# ESP32-C5 register map
Vendor: ESPRESSIF SYSTEMS (SHANGHAI) CO., LTD.; Series: ESP32 C-Series; File version: 1
CPU: RV32IMAC r0p0, little endian, no MPU, no FPU, 0 interrupt priority bits
Address unit: 32 bits
Registers are 32-bit, read-write, reset 0x0 unless marked. A register's access mark holds for its fields unless they carry their own. Offsets are from the block's base; [hi:lo] are bit positions; {n}, {i} and the like mark numbered series.

## GPIO_EXT — GPIO_EXT Peripheral
Base 0x60091E00
0x00 CLOCK_GATE — Clock Gating Configure Register
  [0] CLK_EN — Clock enable bit of configuration registers for sigma delta modulation.
0x04 SIGMADELTA_MISC — MISC Register
  [0] SIGMADELTA_CLK_EN — Configures whether or not to enable the clock for sigma delta modulation.\\ 0: Not enable\\ 1: Enable\\%\label{fielddesc:GPIOSDSPISWAP}- [GPIOSD_SPI_SWAP] Reserved.
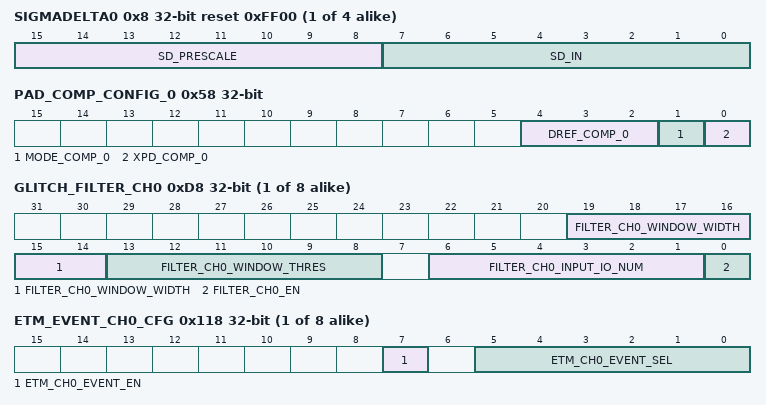
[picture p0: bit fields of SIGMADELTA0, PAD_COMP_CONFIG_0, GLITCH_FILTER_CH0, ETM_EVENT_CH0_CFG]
{0x8+4i} SIGMADELTA{i} (i=0..3) reset 0xFF00 — Duty cycle configuration register for SDM channel {i}
  [15:8] SD_PRESCALE — Configures the divider value to divide IO MUX operating clock. \\
  [7:0] SD_IN — Configures the duty cycle of sigma delta modulation output. \\
0x58 PAD_COMP_CONFIG_0 — Configuration register for zero-crossing detection
  [4:2] DREF_COMP_0 — Configures the internal reference voltage for analog PAD voltage coparator. \\ 0: Internal reference voltage is 0 * VDDPST1\\ 1: Internal reference voltage is 0.1 * VDDPST1\\ …...\\ 6: Internal reference voltage is 0.6 * VDDPST1\\ 7: Internal reference voltage is 0.7 * VDDPST1\\
  [1] MODE_COMP_0 — Configures the reference voltage for analog PAD voltage comparater.. \\ 0: Reference voltage is the internal reference voltage, meanwhile GPIO8 PAD can be used as a regular GPIO\\ 1: Reference voltage is the voltage on the GPIO8 PAD\\
  [0] XPD_COMP_0 — Configures whether to enable the function of analog PAD voltage comparator.\\ 0: Disable\\ 1: Enable\\
0x5C PAD_COMP_FILTER_0 — Configuration register for interrupt source mask period of zero-crossing detection
  [31:0] ZERO_DET_FILTER_CNT_0 — Configures the period of masking new interrupt source foe analog PAD voltage comparator.\\ Measurement unit: IO MUX operating clock cycle\\
{0xD8+4i} GLITCH_FILTER_CH{i} (i=0..7) — Glitch Filter Configure Register of Channel{i}
  [19:14] FILTER_CH0_WINDOW_WIDTH — Configures the window width for Glitch Filter. The effective value of window width is 0 ~ 63. \\ Measurement unit: IO MUX operating clock cycle\\
  [13:8] FILTER_CH0_WINDOW_THRES — Configures the window threshold for Glitch Filter. The window threshold should be less than or equal to GPIOSD_FILTER_CH%s_WINDOW_WIDTH.\\ %see DOC-4768\\ Measurement unit: IO MUX operating clock cycle\\
  [6:1] FILTER_CH0_INPUT_IO_NUM — Configures to select the input GPIO for Glitch Filter. \\ 0: Select GPIO0\\ 1: Select GPIO1\\ ......\\ 27: Select GPIO27\\ 28: Select GPIO28\\ 29 ~ 63: Reserved\\
  [0] FILTER_CH0_EN — Configures whether or not to enable channel %s of Glitch Filter.\\ 0: Not enable\\ 1: Enable\\
{0x118+4i} ETM_EVENT_CH{i}_CFG (i=0..7) — Etm Config register of Channel{i}
  [7] ETM_CH0_EVENT_EN — Configures whether or not to enable ETM event send.\\ 0: Not enable\\ 1: Enable\\
  [5:0] ETM_CH0_EVENT_SEL — Configures to select GPIO for ETM event channel.\\ 0: Select GPIO0\\ 1: Select GPIO1\\ ......\\ 27: Select GPIO27\\ 28: Select GPIO28\\ 29 ~ 63: Reserved\\
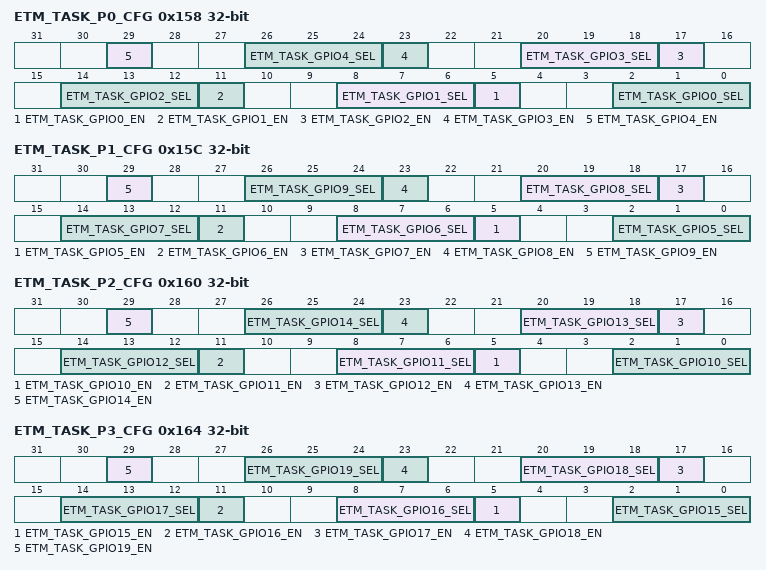
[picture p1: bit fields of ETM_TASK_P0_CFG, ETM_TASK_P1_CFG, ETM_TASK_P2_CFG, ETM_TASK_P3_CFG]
0x158 ETM_TASK_P0_CFG — GPIO selection register 0 for ETM
  [6n+5] ETM_TASK_GPIO{n}_EN (n=0..4) — Configures whether or not to enable GPIO{6n+5} to response ETM task.\\ 0: Not enable\\ 1: Enable\\
  [26:24] ETM_TASK_GPIO4_SEL — Configures to select an ETM task channel for GPIO24.\\ 0: Select channel 0\\ 1: Select channel 1\\ ......\\ 7: Select channel 7\\%\label{fielddesc:GPIOSDETMTASKGPIO1EN}- [GPIOSD_ETM_TASK_GPIO1_EN] Enable bit of GPIO response etm task. %\label{fielddesc:GPIOSDETMTASKGPIO1SEL}- [GPIOSD_ETM_TASK_GPIO1_SEL] GPIO choose a etm task channel. %\label{fielddesc:GPIOSDETMTASKGPIO2EN}- [GPIOSD_ETM_TASK_GPIO2_EN] Enable bit of GPIO response etm task. %\label{fielddesc:GPIOSDETMTASKGPIO2SEL}- [GPIOSD_ETM_TASK_GPIO2_SEL] GPIO choose a etm task channel. %\label{fielddesc:GPIOSDETMTASKGPIO3EN}\item [GPIOSD_ETM_TASK_GPIO3_EN] Enable bit of GPIO response etm task. %\label{fielddesc:GPIOSDETMTASKGPIO3SEL}\item [GPIOSD_ETM_TASK_GPIO3_SEL] GPIO choose a etm task channel.
  [20:18] ETM_TASK_GPIO3_SEL — Configures to select an ETM task channel for GPIO18.\\ 0: Select channel 0\\ 1: Select channel 1\\ ......\\ 7: Select channel 7\\%\label{fielddesc:GPIOSDETMTASKGPIO1EN}- [GPIOSD_ETM_TASK_GPIO1_EN] Enable bit of GPIO response etm task. %\label{fielddesc:GPIOSDETMTASKGPIO1SEL}- [GPIOSD_ETM_TASK_GPIO1_SEL] GPIO choose a etm task channel. %\label{fielddesc:GPIOSDETMTASKGPIO2EN}- [GPIOSD_ETM_TASK_GPIO2_EN] Enable bit of GPIO response etm task. %\label{fielddesc:GPIOSDETMTASKGPIO2SEL}- [GPIOSD_ETM_TASK_GPIO2_SEL] GPIO choose a etm task channel. %\label{fielddesc:GPIOSDETMTASKGPIO3EN}\item [GPIOSD_ETM_TASK_GPIO3_EN] Enable bit of GPIO response etm task. %\label{fielddesc:GPIOSDETMTASKGPIO3SEL}\item [GPIOSD_ETM_TASK_GPIO3_SEL] GPIO choose a etm task channel.
  [14:12] ETM_TASK_GPIO2_SEL — Configures to select an ETM task channel for GPIO12.\\ 0: Select channel 0\\ 1: Select channel 1\\ ......\\ 7: Select channel 7\\%\label{fielddesc:GPIOSDETMTASKGPIO1EN}- [GPIOSD_ETM_TASK_GPIO1_EN] Enable bit of GPIO response etm task. %\label{fielddesc:GPIOSDETMTASKGPIO1SEL}- [GPIOSD_ETM_TASK_GPIO1_SEL] GPIO choose a etm task channel. %\label{fielddesc:GPIOSDETMTASKGPIO2EN}- [GPIOSD_ETM_TASK_GPIO2_EN] Enable bit of GPIO response etm task. %\label{fielddesc:GPIOSDETMTASKGPIO2SEL}- [GPIOSD_ETM_TASK_GPIO2_SEL] GPIO choose a etm task channel. %\label{fielddesc:GPIOSDETMTASKGPIO3EN}\item [GPIOSD_ETM_TASK_GPIO3_EN] Enable bit of GPIO response etm task. %\label{fielddesc:GPIOSDETMTASKGPIO3SEL}\item [GPIOSD_ETM_TASK_GPIO3_SEL] GPIO choose a etm task channel.
  [8:6] ETM_TASK_GPIO1_SEL — Configures to select an ETM task channel for GPIO6.\\ 0: Select channel 0\\ 1: Select channel 1\\ ......\\ 7: Select channel 7\\%\label{fielddesc:GPIOSDETMTASKGPIO1EN}- [GPIOSD_ETM_TASK_GPIO1_EN] Enable bit of GPIO response etm task. %\label{fielddesc:GPIOSDETMTASKGPIO1SEL}- [GPIOSD_ETM_TASK_GPIO1_SEL] GPIO choose a etm task channel. %\label{fielddesc:GPIOSDETMTASKGPIO2EN}- [GPIOSD_ETM_TASK_GPIO2_EN] Enable bit of GPIO response etm task. %\label{fielddesc:GPIOSDETMTASKGPIO2SEL}- [GPIOSD_ETM_TASK_GPIO2_SEL] GPIO choose a etm task channel. %\label{fielddesc:GPIOSDETMTASKGPIO3EN}\item [GPIOSD_ETM_TASK_GPIO3_EN] Enable bit of GPIO response etm task. %\label{fielddesc:GPIOSDETMTASKGPIO3SEL}\item [GPIOSD_ETM_TASK_GPIO3_SEL] GPIO choose a etm task channel.
  [2:0] ETM_TASK_GPIO0_SEL — Configures to select an ETM task channel for GPIO0.\\ 0: Select channel 0\\ 1: Select channel 1\\ ......\\ 7: Select channel 7\\%\label{fielddesc:GPIOSDETMTASKGPIO1EN}- [GPIOSD_ETM_TASK_GPIO1_EN] Enable bit of GPIO response etm task. %\label{fielddesc:GPIOSDETMTASKGPIO1SEL}- [GPIOSD_ETM_TASK_GPIO1_SEL] GPIO choose a etm task channel. %\label{fielddesc:GPIOSDETMTASKGPIO2EN}- [GPIOSD_ETM_TASK_GPIO2_EN] Enable bit of GPIO response etm task. %\label{fielddesc:GPIOSDETMTASKGPIO2SEL}- [GPIOSD_ETM_TASK_GPIO2_SEL] GPIO choose a etm task channel. %\label{fielddesc:GPIOSDETMTASKGPIO3EN}\item [GPIOSD_ETM_TASK_GPIO3_EN] Enable bit of GPIO response etm task. %\label{fielddesc:GPIOSDETMTASKGPIO3SEL}\item [GPIOSD_ETM_TASK_GPIO3_SEL] GPIO choose a etm task channel.
0x15C ETM_TASK_P1_CFG — GPIO selection register 1 for ETM
  [6n-25] ETM_TASK_GPIO{n}_EN (n=5..9) — Configures whether or not to enable GPIO{6n-25} to response ETM task.\\ 0: Not enable\\ 1: Enable\\
  [26:24] ETM_TASK_GPIO9_SEL — Configures to select an ETM task channel for GPIO24.\\ 0: Select channel 0\\ 1: Select channel 1\\ ......\\ 7: Select channel 7\\%\label{fielddesc:GPIOSDETMTASKGPIO1EN}- [GPIOSD_ETM_TASK_GPIO1_EN] Enable bit of GPIO response etm task. %\label{fielddesc:GPIOSDETMTASKGPIO1SEL}- [GPIOSD_ETM_TASK_GPIO1_SEL] GPIO choose a etm task channel. %\label{fielddesc:GPIOSDETMTASKGPIO2EN}- [GPIOSD_ETM_TASK_GPIO2_EN] Enable bit of GPIO response etm task. %\label{fielddesc:GPIOSDETMTASKGPIO2SEL}- [GPIOSD_ETM_TASK_GPIO2_SEL] GPIO choose a etm task channel. %\label{fielddesc:GPIOSDETMTASKGPIO3EN}\item [GPIOSD_ETM_TASK_GPIO3_EN] Enable bit of GPIO response etm task. %\label{fielddesc:GPIOSDETMTASKGPIO3SEL}\item [GPIOSD_ETM_TASK_GPIO3_SEL] GPIO choose a etm task channel.
  [20:18] ETM_TASK_GPIO8_SEL — Configures to select an ETM task channel for GPIO18.\\ 0: Select channel 0\\ 1: Select channel 1\\ ......\\ 7: Select channel 7\\%\label{fielddesc:GPIOSDETMTASKGPIO1EN}- [GPIOSD_ETM_TASK_GPIO1_EN] Enable bit of GPIO response etm task. %\label{fielddesc:GPIOSDETMTASKGPIO1SEL}- [GPIOSD_ETM_TASK_GPIO1_SEL] GPIO choose a etm task channel. %\label{fielddesc:GPIOSDETMTASKGPIO2EN}- [GPIOSD_ETM_TASK_GPIO2_EN] Enable bit of GPIO response etm task. %\label{fielddesc:GPIOSDETMTASKGPIO2SEL}- [GPIOSD_ETM_TASK_GPIO2_SEL] GPIO choose a etm task channel. %\label{fielddesc:GPIOSDETMTASKGPIO3EN}\item [GPIOSD_ETM_TASK_GPIO3_EN] Enable bit of GPIO response etm task. %\label{fielddesc:GPIOSDETMTASKGPIO3SEL}\item [GPIOSD_ETM_TASK_GPIO3_SEL] GPIO choose a etm task channel.
  [14:12] ETM_TASK_GPIO7_SEL — Configures to select an ETM task channel for GPIO12.\\ 0: Select channel 0\\ 1: Select channel 1\\ ......\\ 7: Select channel 7\\%\label{fielddesc:GPIOSDETMTASKGPIO1EN}- [GPIOSD_ETM_TASK_GPIO1_EN] Enable bit of GPIO response etm task. %\label{fielddesc:GPIOSDETMTASKGPIO1SEL}- [GPIOSD_ETM_TASK_GPIO1_SEL] GPIO choose a etm task channel. %\label{fielddesc:GPIOSDETMTASKGPIO2EN}- [GPIOSD_ETM_TASK_GPIO2_EN] Enable bit of GPIO response etm task. %\label{fielddesc:GPIOSDETMTASKGPIO2SEL}- [GPIOSD_ETM_TASK_GPIO2_SEL] GPIO choose a etm task channel. %\label{fielddesc:GPIOSDETMTASKGPIO3EN}\item [GPIOSD_ETM_TASK_GPIO3_EN] Enable bit of GPIO response etm task. %\label{fielddesc:GPIOSDETMTASKGPIO3SEL}\item [GPIOSD_ETM_TASK_GPIO3_SEL] GPIO choose a etm task channel.
  [8:6] ETM_TASK_GPIO6_SEL — Configures to select an ETM task channel for GPIO6.\\ 0: Select channel 0\\ 1: Select channel 1\\ ......\\ 7: Select channel 7\\%\label{fielddesc:GPIOSDETMTASKGPIO1EN}- [GPIOSD_ETM_TASK_GPIO1_EN] Enable bit of GPIO response etm task. %\label{fielddesc:GPIOSDETMTASKGPIO1SEL}- [GPIOSD_ETM_TASK_GPIO1_SEL] GPIO choose a etm task channel. %\label{fielddesc:GPIOSDETMTASKGPIO2EN}- [GPIOSD_ETM_TASK_GPIO2_EN] Enable bit of GPIO response etm task. %\label{fielddesc:GPIOSDETMTASKGPIO2SEL}- [GPIOSD_ETM_TASK_GPIO2_SEL] GPIO choose a etm task channel. %\label{fielddesc:GPIOSDETMTASKGPIO3EN}\item [GPIOSD_ETM_TASK_GPIO3_EN] Enable bit of GPIO response etm task. %\label{fielddesc:GPIOSDETMTASKGPIO3SEL}\item [GPIOSD_ETM_TASK_GPIO3_SEL] GPIO choose a etm task channel.
  [2:0] ETM_TASK_GPIO5_SEL — Configures to select an ETM task channel for GPIO0.\\ 0: Select channel 0\\ 1: Select channel 1\\ ......\\ 7: Select channel 7\\%\label{fielddesc:GPIOSDETMTASKGPIO1EN}- [GPIOSD_ETM_TASK_GPIO1_EN] Enable bit of GPIO response etm task. %\label{fielddesc:GPIOSDETMTASKGPIO1SEL}- [GPIOSD_ETM_TASK_GPIO1_SEL] GPIO choose a etm task channel. %\label{fielddesc:GPIOSDETMTASKGPIO2EN}- [GPIOSD_ETM_TASK_GPIO2_EN] Enable bit of GPIO response etm task. %\label{fielddesc:GPIOSDETMTASKGPIO2SEL}- [GPIOSD_ETM_TASK_GPIO2_SEL] GPIO choose a etm task channel. %\label{fielddesc:GPIOSDETMTASKGPIO3EN}\item [GPIOSD_ETM_TASK_GPIO3_EN] Enable bit of GPIO response etm task. %\label{fielddesc:GPIOSDETMTASKGPIO3SEL}\item [GPIOSD_ETM_TASK_GPIO3_SEL] GPIO choose a etm task channel.
0x160 ETM_TASK_P2_CFG — GPIO selection register 2 for ETM
  [6n-55] ETM_TASK_GPIO{n}_EN (n=10..14) — Configures whether or not to enable GPIO{6n-55} to response ETM task.\\ 0: Not enable\\ 1: Enable\\
  [26:24] ETM_TASK_GPIO14_SEL — Configures to select an ETM task channel for GPIO24.\\ 0: Select channel 0\\ 1: Select channel 1\\ ......\\ 7: Select channel 7\\%\label{fielddesc:GPIOSDETMTASKGPIO1EN}- [GPIOSD_ETM_TASK_GPIO1_EN] Enable bit of GPIO response etm task. %\label{fielddesc:GPIOSDETMTASKGPIO1SEL}- [GPIOSD_ETM_TASK_GPIO1_SEL] GPIO choose a etm task channel. %\label{fielddesc:GPIOSDETMTASKGPIO2EN}- [GPIOSD_ETM_TASK_GPIO2_EN] Enable bit of GPIO response etm task. %\label{fielddesc:GPIOSDETMTASKGPIO2SEL}- [GPIOSD_ETM_TASK_GPIO2_SEL] GPIO choose a etm task channel. %\label{fielddesc:GPIOSDETMTASKGPIO3EN}\item [GPIOSD_ETM_TASK_GPIO3_EN] Enable bit of GPIO response etm task. %\label{fielddesc:GPIOSDETMTASKGPIO3SEL}\item [GPIOSD_ETM_TASK_GPIO3_SEL] GPIO choose a etm task channel.
  [20:18] ETM_TASK_GPIO13_SEL — Configures to select an ETM task channel for GPIO18.\\ 0: Select channel 0\\ 1: Select channel 1\\ ......\\ 7: Select channel 7\\%\label{fielddesc:GPIOSDETMTASKGPIO1EN}- [GPIOSD_ETM_TASK_GPIO1_EN] Enable bit of GPIO response etm task. %\label{fielddesc:GPIOSDETMTASKGPIO1SEL}- [GPIOSD_ETM_TASK_GPIO1_SEL] GPIO choose a etm task channel. %\label{fielddesc:GPIOSDETMTASKGPIO2EN}- [GPIOSD_ETM_TASK_GPIO2_EN] Enable bit of GPIO response etm task. %\label{fielddesc:GPIOSDETMTASKGPIO2SEL}- [GPIOSD_ETM_TASK_GPIO2_SEL] GPIO choose a etm task channel. %\label{fielddesc:GPIOSDETMTASKGPIO3EN}\item [GPIOSD_ETM_TASK_GPIO3_EN] Enable bit of GPIO response etm task. %\label{fielddesc:GPIOSDETMTASKGPIO3SEL}\item [GPIOSD_ETM_TASK_GPIO3_SEL] GPIO choose a etm task channel.
  [14:12] ETM_TASK_GPIO12_SEL — Configures to select an ETM task channel for GPIO12.\\ 0: Select channel 0\\ 1: Select channel 1\\ ......\\ 7: Select channel 7\\%\label{fielddesc:GPIOSDETMTASKGPIO1EN}- [GPIOSD_ETM_TASK_GPIO1_EN] Enable bit of GPIO response etm task. %\label{fielddesc:GPIOSDETMTASKGPIO1SEL}- [GPIOSD_ETM_TASK_GPIO1_SEL] GPIO choose a etm task channel. %\label{fielddesc:GPIOSDETMTASKGPIO2EN}- [GPIOSD_ETM_TASK_GPIO2_EN] Enable bit of GPIO response etm task. %\label{fielddesc:GPIOSDETMTASKGPIO2SEL}- [GPIOSD_ETM_TASK_GPIO2_SEL] GPIO choose a etm task channel. %\label{fielddesc:GPIOSDETMTASKGPIO3EN}\item [GPIOSD_ETM_TASK_GPIO3_EN] Enable bit of GPIO response etm task. %\label{fielddesc:GPIOSDETMTASKGPIO3SEL}\item [GPIOSD_ETM_TASK_GPIO3_SEL] GPIO choose a etm task channel.
  [8:6] ETM_TASK_GPIO11_SEL — Configures to select an ETM task channel for GPIO6.\\ 0: Select channel 0\\ 1: Select channel 1\\ ......\\ 7: Select channel 7\\%\label{fielddesc:GPIOSDETMTASKGPIO1EN}- [GPIOSD_ETM_TASK_GPIO1_EN] Enable bit of GPIO response etm task. %\label{fielddesc:GPIOSDETMTASKGPIO1SEL}- [GPIOSD_ETM_TASK_GPIO1_SEL] GPIO choose a etm task channel. %\label{fielddesc:GPIOSDETMTASKGPIO2EN}- [GPIOSD_ETM_TASK_GPIO2_EN] Enable bit of GPIO response etm task. %\label{fielddesc:GPIOSDETMTASKGPIO2SEL}- [GPIOSD_ETM_TASK_GPIO2_SEL] GPIO choose a etm task channel. %\label{fielddesc:GPIOSDETMTASKGPIO3EN}\item [GPIOSD_ETM_TASK_GPIO3_EN] Enable bit of GPIO response etm task. %\label{fielddesc:GPIOSDETMTASKGPIO3SEL}\item [GPIOSD_ETM_TASK_GPIO3_SEL] GPIO choose a etm task channel.
  [2:0] ETM_TASK_GPIO10_SEL — Configures to select an ETM task channel for GPIO0.\\ 0: Select channel 0\\ 1: Select channel 1\\ ......\\ 7: Select channel 7\\%\label{fielddesc:GPIOSDETMTASKGPIO1EN}- [GPIOSD_ETM_TASK_GPIO1_EN] Enable bit of GPIO response etm task. %\label{fielddesc:GPIOSDETMTASKGPIO1SEL}- [GPIOSD_ETM_TASK_GPIO1_SEL] GPIO choose a etm task channel. %\label{fielddesc:GPIOSDETMTASKGPIO2EN}- [GPIOSD_ETM_TASK_GPIO2_EN] Enable bit of GPIO response etm task. %\label{fielddesc:GPIOSDETMTASKGPIO2SEL}- [GPIOSD_ETM_TASK_GPIO2_SEL] GPIO choose a etm task channel. %\label{fielddesc:GPIOSDETMTASKGPIO3EN}\item [GPIOSD_ETM_TASK_GPIO3_EN] Enable bit of GPIO response etm task. %\label{fielddesc:GPIOSDETMTASKGPIO3SEL}\item [GPIOSD_ETM_TASK_GPIO3_SEL] GPIO choose a etm task channel.
0x164 ETM_TASK_P3_CFG — GPIO selection register 3 for ETM
  [6n-85] ETM_TASK_GPIO{n}_EN (n=15..19) — Configures whether or not to enable GPIO{6n-85} to response ETM task.\\ 0: Not enable\\ 1: Enable\\
  [26:24] ETM_TASK_GPIO19_SEL — Configures to select an ETM task channel for GPIO24.\\ 0: Select channel 0\\ 1: Select channel 1\\ ......\\ 7: Select channel 7\\%\label{fielddesc:GPIOSDETMTASKGPIO1EN}- [GPIOSD_ETM_TASK_GPIO1_EN] Enable bit of GPIO response etm task. %\label{fielddesc:GPIOSDETMTASKGPIO1SEL}- [GPIOSD_ETM_TASK_GPIO1_SEL] GPIO choose a etm task channel. %\label{fielddesc:GPIOSDETMTASKGPIO2EN}- [GPIOSD_ETM_TASK_GPIO2_EN] Enable bit of GPIO response etm task. %\label{fielddesc:GPIOSDETMTASKGPIO2SEL}- [GPIOSD_ETM_TASK_GPIO2_SEL] GPIO choose a etm task channel. %\label{fielddesc:GPIOSDETMTASKGPIO3EN}\item [GPIOSD_ETM_TASK_GPIO3_EN] Enable bit of GPIO response etm task. %\label{fielddesc:GPIOSDETMTASKGPIO3SEL}\item [GPIOSD_ETM_TASK_GPIO3_SEL] GPIO choose a etm task channel.
  [20:18] ETM_TASK_GPIO18_SEL — Configures to select an ETM task channel for GPIO18.\\ 0: Select channel 0\\ 1: Select channel 1\\ ......\\ 7: Select channel 7\\%\label{fielddesc:GPIOSDETMTASKGPIO1EN}- [GPIOSD_ETM_TASK_GPIO1_EN] Enable bit of GPIO response etm task. %\label{fielddesc:GPIOSDETMTASKGPIO1SEL}- [GPIOSD_ETM_TASK_GPIO1_SEL] GPIO choose a etm task channel. %\label{fielddesc:GPIOSDETMTASKGPIO2EN}- [GPIOSD_ETM_TASK_GPIO2_EN] Enable bit of GPIO response etm task. %\label{fielddesc:GPIOSDETMTASKGPIO2SEL}- [GPIOSD_ETM_TASK_GPIO2_SEL] GPIO choose a etm task channel. %\label{fielddesc:GPIOSDETMTASKGPIO3EN}\item [GPIOSD_ETM_TASK_GPIO3_EN] Enable bit of GPIO response etm task. %\label{fielddesc:GPIOSDETMTASKGPIO3SEL}\item [GPIOSD_ETM_TASK_GPIO3_SEL] GPIO choose a etm task channel.
  [14:12] ETM_TASK_GPIO17_SEL — Configures to select an ETM task channel for GPIO12.\\ 0: Select channel 0\\ 1: Select channel 1\\ ......\\ 7: Select channel 7\\%\label{fielddesc:GPIOSDETMTASKGPIO1EN}- [GPIOSD_ETM_TASK_GPIO1_EN] Enable bit of GPIO response etm task. %\label{fielddesc:GPIOSDETMTASKGPIO1SEL}- [GPIOSD_ETM_TASK_GPIO1_SEL] GPIO choose a etm task channel. %\label{fielddesc:GPIOSDETMTASKGPIO2EN}- [GPIOSD_ETM_TASK_GPIO2_EN] Enable bit of GPIO response etm task. %\label{fielddesc:GPIOSDETMTASKGPIO2SEL}- [GPIOSD_ETM_TASK_GPIO2_SEL] GPIO choose a etm task channel. %\label{fielddesc:GPIOSDETMTASKGPIO3EN}\item [GPIOSD_ETM_TASK_GPIO3_EN] Enable bit of GPIO response etm task. %\label{fielddesc:GPIOSDETMTASKGPIO3SEL}\item [GPIOSD_ETM_TASK_GPIO3_SEL] GPIO choose a etm task channel.
  [8:6] ETM_TASK_GPIO16_SEL — Configures to select an ETM task channel for GPIO6.\\ 0: Select channel 0\\ 1: Select channel 1\\ ......\\ 7: Select channel 7\\%\label{fielddesc:GPIOSDETMTASKGPIO1EN}- [GPIOSD_ETM_TASK_GPIO1_EN] Enable bit of GPIO response etm task. %\label{fielddesc:GPIOSDETMTASKGPIO1SEL}- [GPIOSD_ETM_TASK_GPIO1_SEL] GPIO choose a etm task channel. %\label{fielddesc:GPIOSDETMTASKGPIO2EN}- [GPIOSD_ETM_TASK_GPIO2_EN] Enable bit of GPIO response etm task. %\label{fielddesc:GPIOSDETMTASKGPIO2SEL}- [GPIOSD_ETM_TASK_GPIO2_SEL] GPIO choose a etm task channel. %\label{fielddesc:GPIOSDETMTASKGPIO3EN}\item [GPIOSD_ETM_TASK_GPIO3_EN] Enable bit of GPIO response etm task. %\label{fielddesc:GPIOSDETMTASKGPIO3SEL}\item [GPIOSD_ETM_TASK_GPIO3_SEL] GPIO choose a etm task channel.
  [2:0] ETM_TASK_GPIO15_SEL — Configures to select an ETM task channel for GPIO0.\\ 0: Select channel 0\\ 1: Select channel 1\\ ......\\ 7: Select channel 7\\%\label{fielddesc:GPIOSDETMTASKGPIO1EN}- [GPIOSD_ETM_TASK_GPIO1_EN] Enable bit of GPIO response etm task. %\label{fielddesc:GPIOSDETMTASKGPIO1SEL}- [GPIOSD_ETM_TASK_GPIO1_SEL] GPIO choose a etm task channel. %\label{fielddesc:GPIOSDETMTASKGPIO2EN}- [GPIOSD_ETM_TASK_GPIO2_EN] Enable bit of GPIO response etm task. %\label{fielddesc:GPIOSDETMTASKGPIO2SEL}- [GPIOSD_ETM_TASK_GPIO2_SEL] GPIO choose a etm task channel. %\label{fielddesc:GPIOSDETMTASKGPIO3EN}\item [GPIOSD_ETM_TASK_GPIO3_EN] Enable bit of GPIO response etm task. %\label{fielddesc:GPIOSDETMTASKGPIO3SEL}\item [GPIOSD_ETM_TASK_GPIO3_SEL] GPIO choose a etm task channel.
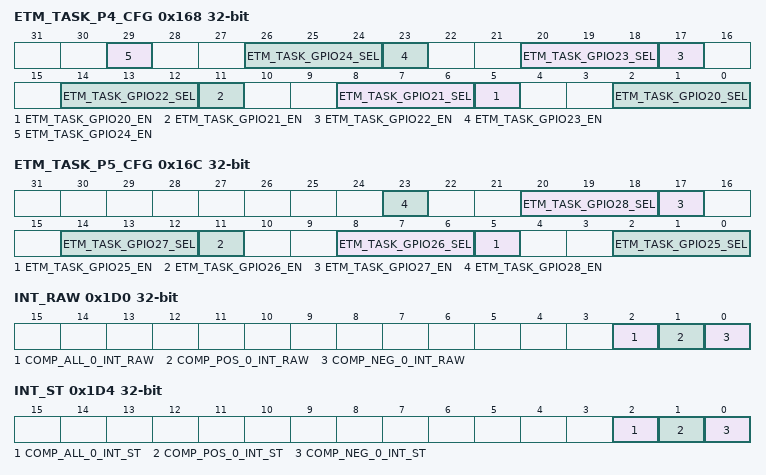
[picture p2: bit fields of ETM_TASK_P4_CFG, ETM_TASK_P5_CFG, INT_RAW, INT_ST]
0x168 ETM_TASK_P4_CFG — GPIO selection register 4 for ETM
  [6n-115] ETM_TASK_GPIO{n}_EN (n=20..24) — Configures whether or not to enable GPIO{6n-115} to response ETM task.\\ 0: Not enable\\ 1: Enable\\
  [26:24] ETM_TASK_GPIO24_SEL — Configures to select an ETM task channel for GPIO24.\\ 0: Select channel 0\\ 1: Select channel 1\\ ......\\ 7: Select channel 7\\%\label{fielddesc:GPIOSDETMTASKGPIO1EN}- [GPIOSD_ETM_TASK_GPIO1_EN] Enable bit of GPIO response etm task. %\label{fielddesc:GPIOSDETMTASKGPIO1SEL}- [GPIOSD_ETM_TASK_GPIO1_SEL] GPIO choose a etm task channel. %\label{fielddesc:GPIOSDETMTASKGPIO2EN}- [GPIOSD_ETM_TASK_GPIO2_EN] Enable bit of GPIO response etm task. %\label{fielddesc:GPIOSDETMTASKGPIO2SEL}- [GPIOSD_ETM_TASK_GPIO2_SEL] GPIO choose a etm task channel. %\label{fielddesc:GPIOSDETMTASKGPIO3EN}\item [GPIOSD_ETM_TASK_GPIO3_EN] Enable bit of GPIO response etm task. %\label{fielddesc:GPIOSDETMTASKGPIO3SEL}\item [GPIOSD_ETM_TASK_GPIO3_SEL] GPIO choose a etm task channel.
  [20:18] ETM_TASK_GPIO23_SEL — Configures to select an ETM task channel for GPIO18.\\ 0: Select channel 0\\ 1: Select channel 1\\ ......\\ 7: Select channel 7\\%\label{fielddesc:GPIOSDETMTASKGPIO1EN}- [GPIOSD_ETM_TASK_GPIO1_EN] Enable bit of GPIO response etm task. %\label{fielddesc:GPIOSDETMTASKGPIO1SEL}- [GPIOSD_ETM_TASK_GPIO1_SEL] GPIO choose a etm task channel. %\label{fielddesc:GPIOSDETMTASKGPIO2EN}- [GPIOSD_ETM_TASK_GPIO2_EN] Enable bit of GPIO response etm task. %\label{fielddesc:GPIOSDETMTASKGPIO2SEL}- [GPIOSD_ETM_TASK_GPIO2_SEL] GPIO choose a etm task channel. %\label{fielddesc:GPIOSDETMTASKGPIO3EN}\item [GPIOSD_ETM_TASK_GPIO3_EN] Enable bit of GPIO response etm task. %\label{fielddesc:GPIOSDETMTASKGPIO3SEL}\item [GPIOSD_ETM_TASK_GPIO3_SEL] GPIO choose a etm task channel.
  [14:12] ETM_TASK_GPIO22_SEL — Configures to select an ETM task channel for GPIO12.\\ 0: Select channel 0\\ 1: Select channel 1\\ ......\\ 7: Select channel 7\\%\label{fielddesc:GPIOSDETMTASKGPIO1EN}- [GPIOSD_ETM_TASK_GPIO1_EN] Enable bit of GPIO response etm task. %\label{fielddesc:GPIOSDETMTASKGPIO1SEL}- [GPIOSD_ETM_TASK_GPIO1_SEL] GPIO choose a etm task channel. %\label{fielddesc:GPIOSDETMTASKGPIO2EN}- [GPIOSD_ETM_TASK_GPIO2_EN] Enable bit of GPIO response etm task. %\label{fielddesc:GPIOSDETMTASKGPIO2SEL}- [GPIOSD_ETM_TASK_GPIO2_SEL] GPIO choose a etm task channel. %\label{fielddesc:GPIOSDETMTASKGPIO3EN}\item [GPIOSD_ETM_TASK_GPIO3_EN] Enable bit of GPIO response etm task. %\label{fielddesc:GPIOSDETMTASKGPIO3SEL}\item [GPIOSD_ETM_TASK_GPIO3_SEL] GPIO choose a etm task channel.
  [8:6] ETM_TASK_GPIO21_SEL — Configures to select an ETM task channel for GPIO6.\\ 0: Select channel 0\\ 1: Select channel 1\\ ......\\ 7: Select channel 7\\%\label{fielddesc:GPIOSDETMTASKGPIO1EN}- [GPIOSD_ETM_TASK_GPIO1_EN] Enable bit of GPIO response etm task. %\label{fielddesc:GPIOSDETMTASKGPIO1SEL}- [GPIOSD_ETM_TASK_GPIO1_SEL] GPIO choose a etm task channel. %\label{fielddesc:GPIOSDETMTASKGPIO2EN}- [GPIOSD_ETM_TASK_GPIO2_EN] Enable bit of GPIO response etm task. %\label{fielddesc:GPIOSDETMTASKGPIO2SEL}- [GPIOSD_ETM_TASK_GPIO2_SEL] GPIO choose a etm task channel. %\label{fielddesc:GPIOSDETMTASKGPIO3EN}\item [GPIOSD_ETM_TASK_GPIO3_EN] Enable bit of GPIO response etm task. %\label{fielddesc:GPIOSDETMTASKGPIO3SEL}\item [GPIOSD_ETM_TASK_GPIO3_SEL] GPIO choose a etm task channel.
  [2:0] ETM_TASK_GPIO20_SEL — Configures to select an ETM task channel for GPIO0.\\ 0: Select channel 0\\ 1: Select channel 1\\ ......\\ 7: Select channel 7\\%\label{fielddesc:GPIOSDETMTASKGPIO1EN}- [GPIOSD_ETM_TASK_GPIO1_EN] Enable bit of GPIO response etm task. %\label{fielddesc:GPIOSDETMTASKGPIO1SEL}- [GPIOSD_ETM_TASK_GPIO1_SEL] GPIO choose a etm task channel. %\label{fielddesc:GPIOSDETMTASKGPIO2EN}- [GPIOSD_ETM_TASK_GPIO2_EN] Enable bit of GPIO response etm task. %\label{fielddesc:GPIOSDETMTASKGPIO2SEL}- [GPIOSD_ETM_TASK_GPIO2_SEL] GPIO choose a etm task channel. %\label{fielddesc:GPIOSDETMTASKGPIO3EN}\item [GPIOSD_ETM_TASK_GPIO3_EN] Enable bit of GPIO response etm task. %\label{fielddesc:GPIOSDETMTASKGPIO3SEL}\item [GPIOSD_ETM_TASK_GPIO3_SEL] GPIO choose a etm task channel.
0x16C ETM_TASK_P5_CFG — GPIO selection register 5 for ETM
  [6n-145] ETM_TASK_GPIO{n}_EN (n=25..28) — Configures whether or not to enable GPIO{6n-145} to response ETM task.\\ 0: Not enable\\ 1: Enable\\
  [20:18] ETM_TASK_GPIO28_SEL — Configures to select an ETM task channel for GPIO18.\\ 0: Select channel 0\\ 1: Select channel 1\\ ......\\ 7: Select channel 7\\%\label{fielddesc:GPIOSDETMTASKGPIO1EN}- [GPIOSD_ETM_TASK_GPIO1_EN] Enable bit of GPIO response etm task. %\label{fielddesc:GPIOSDETMTASKGPIO1SEL}- [GPIOSD_ETM_TASK_GPIO1_SEL] GPIO choose a etm task channel. %\label{fielddesc:GPIOSDETMTASKGPIO2EN}- [GPIOSD_ETM_TASK_GPIO2_EN] Enable bit of GPIO response etm task. %\label{fielddesc:GPIOSDETMTASKGPIO2SEL}- [GPIOSD_ETM_TASK_GPIO2_SEL] GPIO choose a etm task channel. %\label{fielddesc:GPIOSDETMTASKGPIO3EN}\item [GPIOSD_ETM_TASK_GPIO3_EN] Enable bit of GPIO response etm task. %\label{fielddesc:GPIOSDETMTASKGPIO3SEL}\item [GPIOSD_ETM_TASK_GPIO3_SEL] GPIO choose a etm task channel.
  [14:12] ETM_TASK_GPIO27_SEL — Configures to select an ETM task channel for GPIO12.\\ 0: Select channel 0\\ 1: Select channel 1\\ ......\\ 7: Select channel 7\\%\label{fielddesc:GPIOSDETMTASKGPIO1EN}- [GPIOSD_ETM_TASK_GPIO1_EN] Enable bit of GPIO response etm task. %\label{fielddesc:GPIOSDETMTASKGPIO1SEL}- [GPIOSD_ETM_TASK_GPIO1_SEL] GPIO choose a etm task channel. %\label{fielddesc:GPIOSDETMTASKGPIO2EN}- [GPIOSD_ETM_TASK_GPIO2_EN] Enable bit of GPIO response etm task. %\label{fielddesc:GPIOSDETMTASKGPIO2SEL}- [GPIOSD_ETM_TASK_GPIO2_SEL] GPIO choose a etm task channel. %\label{fielddesc:GPIOSDETMTASKGPIO3EN}\item [GPIOSD_ETM_TASK_GPIO3_EN] Enable bit of GPIO response etm task. %\label{fielddesc:GPIOSDETMTASKGPIO3SEL}\item [GPIOSD_ETM_TASK_GPIO3_SEL] GPIO choose a etm task channel.
  [8:6] ETM_TASK_GPIO26_SEL — Configures to select an ETM task channel for GPIO6.\\ 0: Select channel 0\\ 1: Select channel 1\\ ......\\ 7: Select channel 7\\%\label{fielddesc:GPIOSDETMTASKGPIO1EN}- [GPIOSD_ETM_TASK_GPIO1_EN] Enable bit of GPIO response etm task. %\label{fielddesc:GPIOSDETMTASKGPIO1SEL}- [GPIOSD_ETM_TASK_GPIO1_SEL] GPIO choose a etm task channel. %\label{fielddesc:GPIOSDETMTASKGPIO2EN}- [GPIOSD_ETM_TASK_GPIO2_EN] Enable bit of GPIO response etm task. %\label{fielddesc:GPIOSDETMTASKGPIO2SEL}- [GPIOSD_ETM_TASK_GPIO2_SEL] GPIO choose a etm task channel. %\label{fielddesc:GPIOSDETMTASKGPIO3EN}\item [GPIOSD_ETM_TASK_GPIO3_EN] Enable bit of GPIO response etm task. %\label{fielddesc:GPIOSDETMTASKGPIO3SEL}\item [GPIOSD_ETM_TASK_GPIO3_SEL] GPIO choose a etm task channel.
  [2:0] ETM_TASK_GPIO25_SEL — Configures to select an ETM task channel for GPIO0.\\ 0: Select channel 0\\ 1: Select channel 1\\ ......\\ 7: Select channel 7\\%\label{fielddesc:GPIOSDETMTASKGPIO1EN}- [GPIOSD_ETM_TASK_GPIO1_EN] Enable bit of GPIO response etm task. %\label{fielddesc:GPIOSDETMTASKGPIO1SEL}- [GPIOSD_ETM_TASK_GPIO1_SEL] GPIO choose a etm task channel. %\label{fielddesc:GPIOSDETMTASKGPIO2EN}- [GPIOSD_ETM_TASK_GPIO2_EN] Enable bit of GPIO response etm task. %\label{fielddesc:GPIOSDETMTASKGPIO2SEL}- [GPIOSD_ETM_TASK_GPIO2_SEL] GPIO choose a etm task channel. %\label{fielddesc:GPIOSDETMTASKGPIO3EN}\item [GPIOSD_ETM_TASK_GPIO3_EN] Enable bit of GPIO response etm task. %\label{fielddesc:GPIOSDETMTASKGPIO3SEL}\item [GPIOSD_ETM_TASK_GPIO3_SEL] GPIO choose a etm task channel.
0x1D0 INT_RAW ro — GPIO_EXT interrupt raw register
  [2] COMP_ALL_0_INT_RAW — analog comparator neg or pos edge interrupt raw
  [1] COMP_POS_0_INT_RAW — analog comparator neg edge interrupt raw
  [0] COMP_NEG_0_INT_RAW — analog comparator pos edge interrupt raw
0x1D4 INT_ST ro — GPIO_EXT interrupt masked register
  [2] COMP_ALL_0_INT_ST — analog comparator neg or pos edge interrupt status
  [1] COMP_POS_0_INT_ST — analog comparator neg edge interrupt status
  [0] COMP_NEG_0_INT_ST — analog comparator pos edge interrupt status
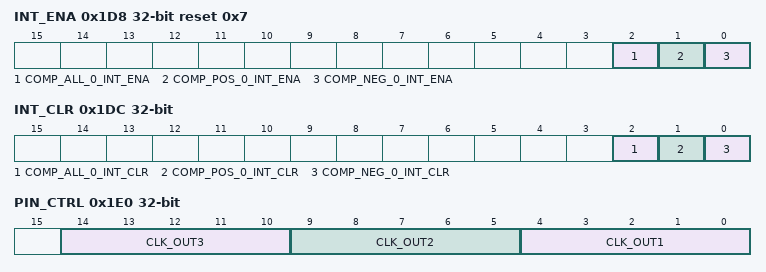
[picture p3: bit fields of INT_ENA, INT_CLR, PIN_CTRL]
0x1D8 INT_ENA reset 0x7 — GPIO_EXT interrupt enable register
  [2] COMP_ALL_0_INT_ENA — analog comparator neg or pos edge interrupt enable
  [1] COMP_POS_0_INT_ENA — analog comparator neg edge interrupt enable
  [0] COMP_NEG_0_INT_ENA — analog comparator pos edge interrupt enable
0x1DC INT_CLR wo — GPIO_EXT interrupt clear register
  [2] COMP_ALL_0_INT_CLR — analog comparator neg or pos edge interrupt clear
  [1] COMP_POS_0_INT_CLR — analog comparator neg edge interrupt clear
  [0] COMP_NEG_0_INT_CLR — analog comparator pos edge interrupt clear
0x1E0 PIN_CTRL — Clock Output Configuration Register
  [14:10] CLK_OUT3 — If you want to output clock for I2S to CLK_OUT_out3, set this register to 0x0. CLK_OUT_out3 can be found in peripheral output signals.
  [9:5] CLK_OUT2 — If you want to output clock for I2S to CLK_OUT_out2, set this register to 0x0. CLK_OUT_out2 can be found in peripheral output signals.
  [4:0] CLK_OUT1 — If you want to output clock for I2S to CLK_OUT_out1, set this register to 0x0. CLK_OUT_out1 can be found in peripheral output signals.
0x1FC VERSION reset 0x2312140 — Version Control Register
  [27:0] DATE — Version control register.
